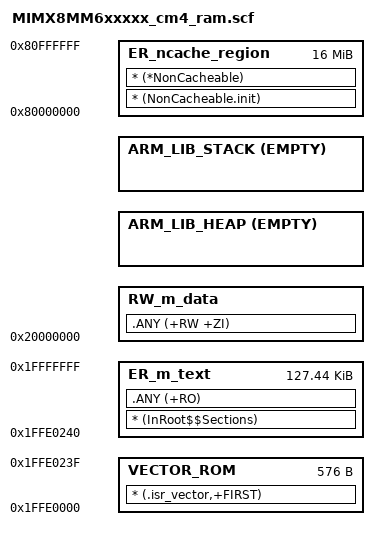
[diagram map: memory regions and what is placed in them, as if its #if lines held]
#!armclang --target=arm-arm-none-eabi -mcpu=cortex-m4 -E -x c
/*
** ###################################################################
**     Processors:          MIMX8MM6CVTKZ
**                          MIMX8MM6DVTLZ
**
**     Compiler:            Keil ARM C/C++ Compiler
**     Reference manual:    MX8MMRM, Rev. 0, 02/2019
**     Version:             rev. 4.0, 2019-02-18
**     Build:               b200330
**
**     Abstract:
**         Linker file for the Keil ARM C/C++ Compiler
**
**     Copyright 2016 Freescale Semiconductor, Inc.
**     Copyright 2016-2020 NXP
**     All rights reserved.
**
**     SPDX-License-Identifier: BSD-3-Clause
**
**     http:                 www.nxp.com
**     mail:                 support@nxp.com
**
** ###################################################################
*/


#define m_interrupts_start             0x1FFE0000
#define m_interrupts_size              0x00000240

#define m_text_start                   0x1FFE0240
#define m_text_size                    0x0001FDC0

#define m_data_start                   0x20000000
#define m_data_size                    0x00020000

#define m_data2_start                  0x80000000
#define m_data2_size                   0x01000000

/* Sizes */
#if (defined(__stack_size__))
  #define Stack_Size                   __stack_size__
#else
  #define Stack_Size                   0x0400
#endif

#if (defined(__heap_size__))
  #define Heap_Size                    __heap_size__
#else
  #define Heap_Size                    0x0400
#endif

LR_cache_region m_interrupts_start m_interrupts_size+m_text_size+m_data_size {   ; load region size_region
  VECTOR_ROM m_interrupts_start m_interrupts_size { ; load address = execution address
    * (.isr_vector,+FIRST)
  }
  ER_m_text m_text_start m_text_size { ; load address = execution address
    * (InRoot$$Sections)
    .ANY (+RO)
  }

  RW_m_data m_data_start m_data_size-Stack_Size-Heap_Size { ; RW data
    .ANY (+RW +ZI)
  }
  ARM_LIB_HEAP +0 EMPTY Heap_Size {    ; Heap region growing up
  }
  ARM_LIB_STACK m_data_start+m_data_size EMPTY -Stack_Size { ; Stack region growing down
  }
}

LR_ncache_region +0 m_data2_size { ; load region LR_ncache_region
  ER_ncache_region m_data2_start m_data2_size {
    * (NonCacheable.init)
    * (*NonCacheable)
  }
}
